# STM32F437xx register map
File version: 1.0
Registers are 32-bit, read-write, reset 0x0 unless marked. A register's access mark holds for its fields unless they carry their own. Offsets are from the block's base; [hi:lo] are bit positions; {n}, {i} and the like mark numbered series; 'fields as' and 'values as' point back to an identical list.

## DCMI
Base 0x50050000
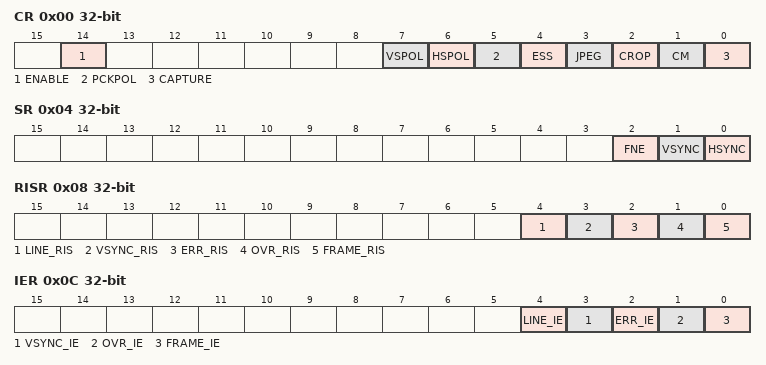
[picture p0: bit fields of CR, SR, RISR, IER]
0x00 CR — DCMI control register 1
  [14] ENABLE, [7] VSPOL, [6] HSPOL, [5] PCKPOL, [4] ESS, [3] JPEG, [2] CROP, [1] CM, [0] CAPTURE
0x04 SR — DCMI status register
  [2] FNE, [1] VSYNC, [0] HSYNC
0x08 RISR — DCMI raw interrupt status register
  [4] LINE_RIS, [3] VSYNC_RIS, [2] ERR_RIS, [1] OVR_RIS, [0] FRAME_RIS
0x0C IER — DCMI interrupt enable register
  [4] LINE_IE, [3] VSYNC_IE, [2] ERR_IE, [1] OVR_IE, [0] FRAME_IE
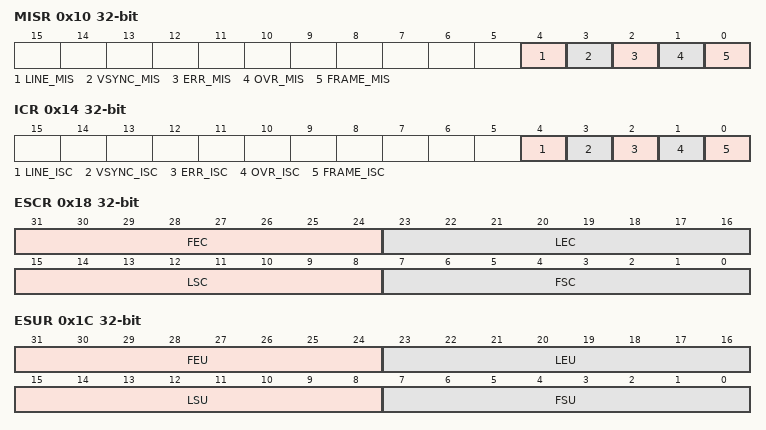
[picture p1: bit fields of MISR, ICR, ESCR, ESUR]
0x10 MISR — DCMI masked interrupt status register
  [4] LINE_MIS, [3] VSYNC_MIS, [2] ERR_MIS, [1] OVR_MIS, [0] FRAME_MIS
0x14 ICR — DCMI interrupt clear register
  [4] LINE_ISC, [3] VSYNC_ISC, [2] ERR_ISC, [1] OVR_ISC, [0] FRAME_ISC
0x18 ESCR — DCMI embedded synchronization code register
  [31:24] FEC, [23:16] LEC, [15:8] LSC, [7:0] FSC
0x1C ESUR — DCMI embedded synchronization unmask register
  [31:24] FEU, [23:16] LEU, [15:8] LSU, [7:0] FSU
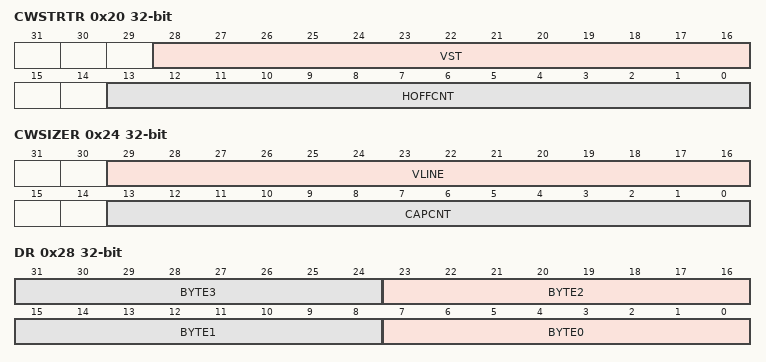
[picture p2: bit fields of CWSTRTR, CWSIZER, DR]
0x20 CWSTRTR — DCMI crop window start
  [28:16] VST, [13:0] HOFFCNT
0x24 CWSIZER — DCMI crop window size
  [29:16] VLINE, [13:0] CAPCNT
0x28 DR — DCMI data register
  [8n+7:8n] BYTE{n} (n=0..3)

## CRYP — Crypto Processor
Base 0x50060000
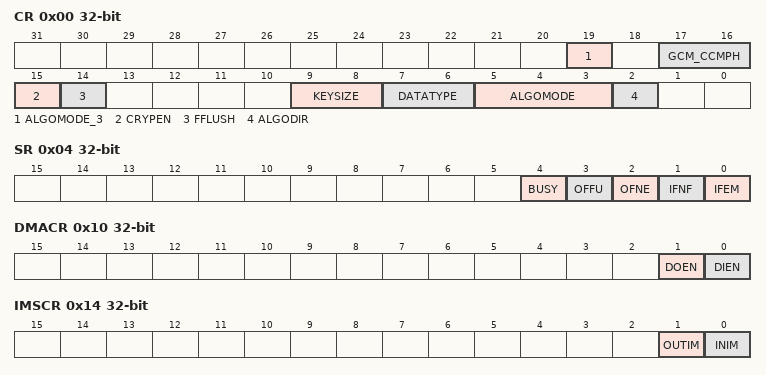
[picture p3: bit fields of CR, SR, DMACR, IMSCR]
0x00 CR — CRYP control register
  [19] ALGOMODE_3, [17:16] GCM_CCMPH, [15] CRYPEN, [14] FFLUSH, [9:8] KEYSIZE, [7:6] DATATYPE, [5:3] ALGOMODE, [2] ALGODIR
0x04 SR — CRYP status register
  [4] BUSY, [3] OFFU, [2] OFNE, [1] IFNF, [0] IFEM
0x08 DIN — CRYP data input register
0x0C DOUT — CRYP data output register
0x10 DMACR — CRYP DMA control register
  [1] DOEN, [0] DIEN
0x14 IMSCR — CRYP interrupt mask set/clear register
  [1] OUTIM, [0] INIM
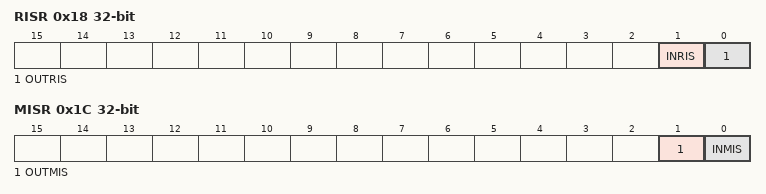
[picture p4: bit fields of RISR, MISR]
0x18 RISR — CRYP raw interrupt status register
  [1] INRIS, [0] OUTRIS
0x1C MISR — CRYP masked interrupt status register
  [1] OUTMIS, [0] INMIS
{0x20+8i} K{i}LR (i=0..3) — CRYP key left register {i}
{0x24+8i} K{i}RR (i=0..3) — CRYP key right register {i}
0x40 IV0LR — CRYP initialization vector left-word register 0
0x44 IV0RR — CRYP initialization vector right-word register 0
0x48 IV1LR — CRYP initialization vector left-word register 1
0x4C IV1RR — CRYP initialization vector right-word register 1
{0x50+4i} CSGCMCCM{i}R (i=0..7) — CRYP GCM/GMAC or CCM/CMAC context swap register {i}
{0x70+4i} CSGCM{i}R (i=0..7) — CRYP GCM/GMAC context swap register {i}

## HASH
Base 0x50060400
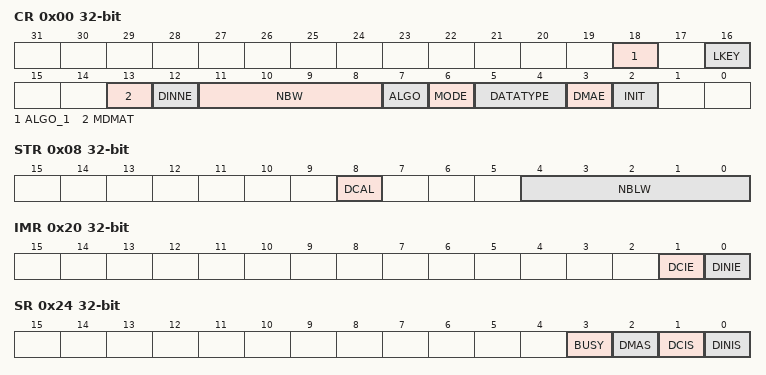
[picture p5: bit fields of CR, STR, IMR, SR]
0x00 CR — HASH control register
  [18] ALGO_1, [16] LKEY, [13] MDMAT, [12] DINNE, [11:8] NBW, [7] ALGO, [6] MODE, [5:4] DATATYPE, [3] DMAE, [2] INIT
0x04 DIN — HASH data input register
0x08 STR — HASH start register
  [8] DCAL, [4:0] NBLW
{0xC+4i} HR{i} (i=0..4) — HASH digest registers
0x20 IMR — HASH interrupt enable register
  [1] DCIE, [0] DINIE
0x24 SR — HASH status register
  [3] BUSY, [2] DMAS, [1] DCIS, [0] DINIS
{0xF8+4i} CSR{i} (i=0..53) — HASH context swap registers
{0x310+4i} DIGEST_HR{i} (i=0..7) — HASH digest registers

## RNG
Base 0x50060800
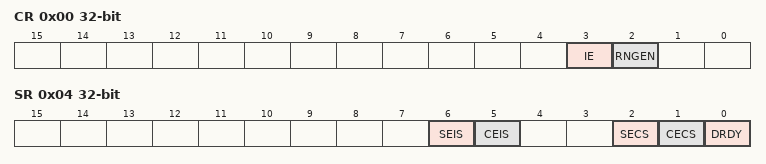
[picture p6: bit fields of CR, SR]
0x00 CR — RNG control register
  [3] IE, [2] RNGEN
0x04 SR — RNG status register
  [6] SEIS, [5] CEIS, [2] SECS, [1] CECS, [0] DRDY
0x08 DR — RNG data register

## FMC_Bank2_3 — Flexible Memory Controller Bank2
Base 0xA0000060
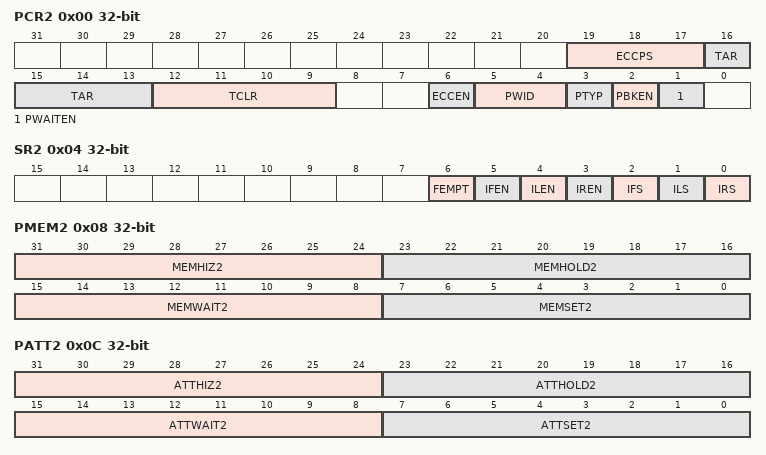
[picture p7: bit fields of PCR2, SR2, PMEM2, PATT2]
0x00 PCR2 — NAND Flash control register 2
  [19:17] ECCPS — ECCPS[1:0] bits (ECC page size)
  [16:13] TAR — TAR[3:0] bits (ALE to RE delay)
  [12:9] TCLR — TCLR[3:0] bits (CLE to RE delay)
  [6] ECCEN — ECC computation logic enable bit
  [5:4] PWID — PWID[1:0] bits (NAND Flash databus width)
  [3] PTYP — Memory type
  [2] PBKEN — PC Card/NAND Flash memory bank enable bit
  [1] PWAITEN — Wait feature enable bit
0x04 SR2 — NAND Flash FIFO status and interrupt register 2
  [6] FEMPT — FIFO empty
  [5] IFEN — Interrupt Falling Edge detection Enable bit
  [4] ILEN — Interrupt Level detection Enable bit
  [3] IREN — Interrupt Rising Edge detection Enable bit
  [2] IFS — Interrupt Falling Edge status
  [1] ILS — Interrupt Level status
  [0] IRS — Interrupt Rising Edge status
0x08 PMEM2 — NAND Flash Common memory space timing register 2
  [31:24] MEMHIZ2 — MEMHIZ2[7:0] bits (Common memory 2 databus HiZ time)
  [23:16] MEMHOLD2 — MEMHOLD2[7:0] bits (Common memory 2 hold time)
  [15:8] MEMWAIT2 — MEMWAIT2[7:0] bits (Common memory 2 wait time)
  [7:0] MEMSET2 — MEMSET2[7:0] bits (Common memory 2 setup time)
0x0C PATT2 — NAND Flash Attribute memory space timing register 2
  [31:24] ATTHIZ2 — ATTHIZ2[7:0] bits (Attribute memory 2 databus HiZ time)
  [23:16] ATTHOLD2 — ATTHOLD2[7:0] bits (Attribute memory 2 hold time)
  [15:8] ATTWAIT2 — ATTWAIT2[7:0] bits (Attribute memory 2 wait time)
  [7:0] ATTSET2 — ATTSET2[7:0] bits (Attribute memory 2 setup time)
0x14 ECCR2 — NAND Flash ECC result registers 2
  [31:0] ECC2 — ECC result
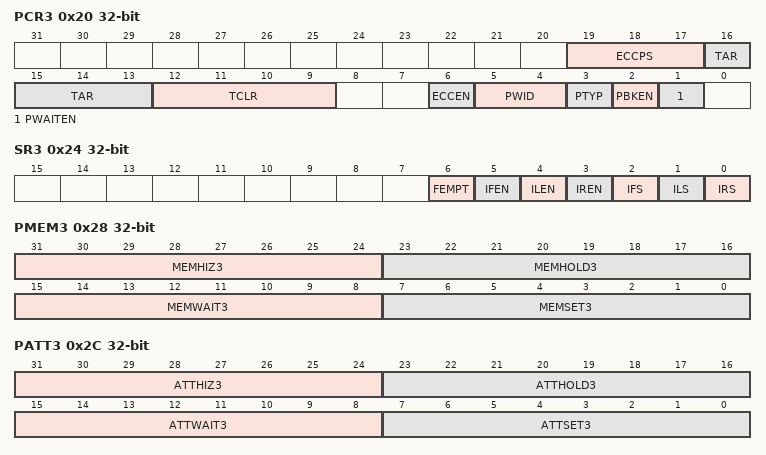
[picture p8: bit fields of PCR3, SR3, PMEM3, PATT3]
0x20 PCR3 — NAND Flash control register 3
  [19:17] ECCPS — ECCPS[2:0] bits (ECC page size)
  [16:13] TAR — TAR[3:0] bits (ALE to RE delay)
  [12:9] TCLR — TCLR[3:0] bits (CLE to RE delay)
  [6] ECCEN — ECC computation logic enable bit
  [5:4] PWID — PWID[1:0] bits (NAND Flash databus width)
  [3] PTYP — Memory type
  [2] PBKEN — PC Card/NAND Flash memory bank enable bit
  [1] PWAITEN — Wait feature enable bit
0x24 SR3 — NAND Flash FIFO status and interrupt register 3
  fields as SR2
0x28 PMEM3 — NAND Flash Common memory space timing register 3
  [31:24] MEMHIZ3 — MEMHIZ3[7:0] bits (Common memory 3 databus HiZ time)
  [23:16] MEMHOLD3 — MEMHOLD3[7:0] bits (Common memory 3 hold time)
  [15:8] MEMWAIT3 — MEMWAIT3[7:0] bits (Common memory 3 wait time)
  [7:0] MEMSET3 — MEMSET3[7:0] bits (Common memory 3 setup time)
0x2C PATT3 — NAND Flash Attribute memory space timing register 3
  [31:24] ATTHIZ3 — ATTHIZ3[7:0] bits (Attribute memory 3 databus HiZ time)
  [23:16] ATTHOLD3 — ATTHOLD3[7:0] bits (Attribute memory 3 hold time)
  [15:8] ATTWAIT3 — ATTWAIT3[7:0] bits (Attribute memory 3 wait time)
  [7:0] ATTSET3 — ATTSET3[7:0] bits (Attribute memory 3 setup time)
0x34 ECCR3 — NAND Flash ECC result registers 3
  [31:0] ECC3 — ECC result

## FMC_Bank1E — Flexible Memory Controller Bank1E
Base 0xA0000104
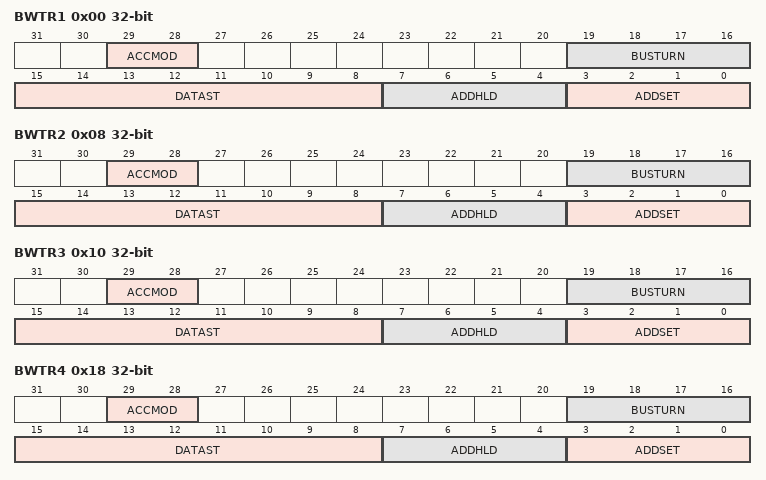
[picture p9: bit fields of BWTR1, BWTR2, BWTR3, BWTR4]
0x00 BWTR1 — NOR/PSRAM write timing registers
  [29:28] ACCMOD — ACCMOD[1:0] bits (Access mode)
  [19:16] BUSTURN — BUSTURN[3:0] bits (Bus turnaround duration)
  [15:8] DATAST — DATAST [3:0] bits (Data-phase duration)
  [7:4] ADDHLD — ADDHLD[3:0] bits (Address-hold phase duration)
  [3:0] ADDSET — ADDSET[3:0] bits (Address setup phase duration)
0x08 BWTR2 — NOR/PSRAM write timing registers
  fields as BWTR1
0x10 BWTR3 — NOR/PSRAM write timing registers
  fields as BWTR1
0x18 BWTR4 — NOR/PSRAM write timing registers
  fields as BWTR1

## FMC_Bank5_6 — Flexible Memory Controller Bank5_6
Base 0xA0000140
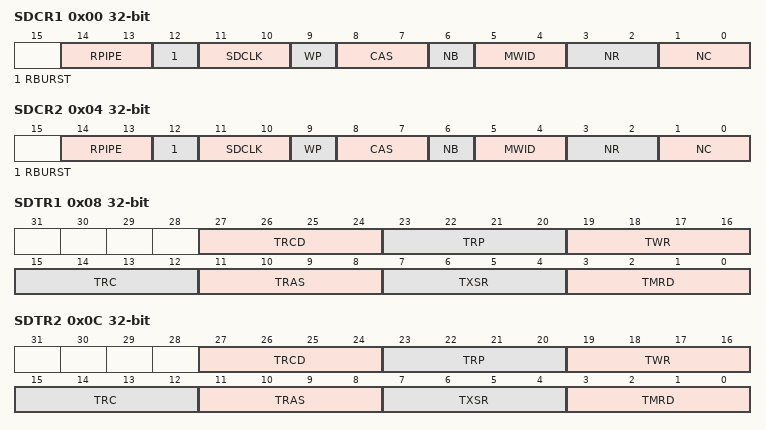
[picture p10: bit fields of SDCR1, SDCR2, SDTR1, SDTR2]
0x00 SDCR1 — SDRAM Control registers
  [14:13] RPIPE — Write protection
  [12] RBURST — Read burst
  [11:10] SDCLK — SDRAM clock configuration
  [9] WP — Write protection
  [8:7] CAS — CAS[1:0] bits (CAS latency)
  [6] NB — Number of internal bank
  [5:4] MWID — NR[1:0] bits (Number of row bits)
  [3:2] NR — NR[1:0] bits (Number of row bits)
  [1:0] NC — NC[1:0] bits (Number of column bits)
0x04 SDCR2 — SDRAM Control registers
  [14:13] RPIPE — RPIPE[1:0](Read pipe)
  [12] RBURST — Read burst
  [11:10] SDCLK — SDCLK[1:0] (SDRAM clock configuration)
  [9] WP — Write protection
  [8:7] CAS — CAS[1:0] bits (CAS latency)
  [6] NB — Number of internal bank
  [5:4] MWID — NR[1:0] bits (Number of row bits)
  [3:2] NR — NR[1:0] bits (Number of row bits)
  [1:0] NC — NC[1:0] bits (Number of column bits)
0x08 SDTR1 — SDRAM Timing registers
  [27:24] TRCD — TRP[2:0] bits (Row to column delay)
  [23:20] TRP — TRP[2:0] bits (Row precharge delay)
  [19:16] TWR — TRC[2:0] bits (Write recovery delay)
  [15:12] TRC — TRC[2:0] bits (Row cycle delay)
  [11:8] TRAS — TRAS[3:0] bits (Self refresh time)
  [7:4] TXSR — TXSR[3:0] bits (Exit self refresh)
  [3:0] TMRD — TMRD[3:0] bits (Load mode register to active)
0x0C SDTR2 — SDRAM Timing registers
  fields as SDTR1
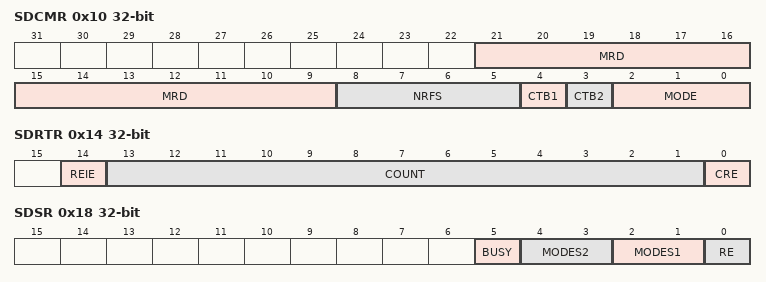
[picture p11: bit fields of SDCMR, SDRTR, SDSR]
0x10 SDCMR — SDRAM Command Mode register
  [21:9] MRD — MRD[12:0] bits (Mode register definition)
  [8:5] NRFS — NRFS[3:0] bits (Number of auto-refresh)
  [4] CTB1 — Command target 1
  [3] CTB2 — Command target 2
  [2:0] MODE — MODE[2:0] bits (Command mode)
0x14 SDRTR — SDRAM Refresh Timer register
  [14] REIE — RES interrupt enable
  [13:1] COUNT — COUNT[12:0] bits (Refresh timer count)
  [0] CRE — Clear refresh error flag
0x18 SDSR — SDRAM Status register
  [5] BUSY — Busy status
  [4:3] MODES2 — MODES2[1:0]bits (Status mode for bank 2)
  [2:1] MODES1 — MODES1[1:0]bits (Status mode for bank 1)
  [0] RE — Refresh error flag

## DBGMCU — Debug MCU
Base 0xE0042000
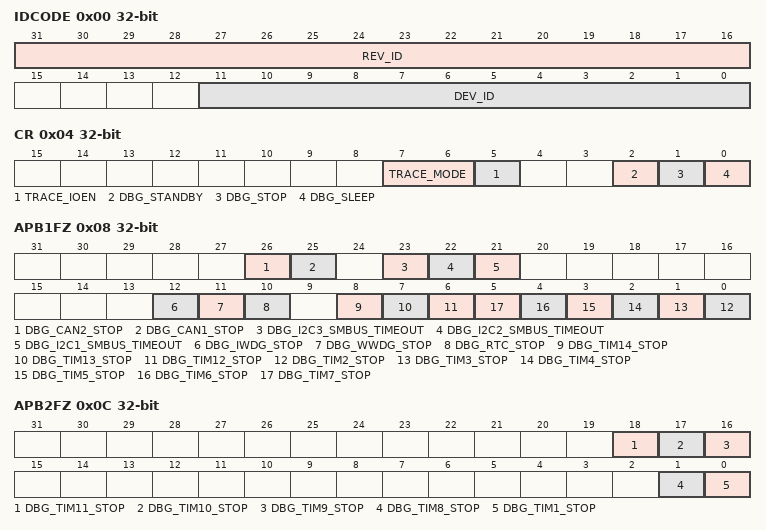
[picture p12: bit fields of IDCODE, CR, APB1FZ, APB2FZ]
0x00 IDCODE — MCU device ID code
  [31:16] REV_ID, [11:0] DEV_ID
0x04 CR — Debug MCU configuration register
  [7:6] TRACE_MODE, [5] TRACE_IOEN, [2] DBG_STANDBY, [1] DBG_STOP, [0] DBG_SLEEP
0x08 APB1FZ — Debug MCU APB1 freeze register
  [26] DBG_CAN2_STOP, [25] DBG_CAN1_STOP, [23] DBG_I2C3_SMBUS_TIMEOUT, [22] DBG_I2C2_SMBUS_TIMEOUT, [21] DBG_I2C1_SMBUS_TIMEOUT, [12] DBG_IWDG_STOP, [11] DBG_WWDG_STOP, [10] DBG_RTC_STOP, [8] DBG_TIM14_STOP, [7] DBG_TIM13_STOP, [6] DBG_TIM12_STOP, [n-2] DBG_TIM{n}_STOP (n=2..7)
0x0C APB2FZ — Debug MCU APB2 freeze register
  [18] DBG_TIM11_STOP, [17] DBG_TIM10_STOP, [16] DBG_TIM9_STOP, [1] DBG_TIM8_STOP, [0] DBG_TIM1_STOP
